AUTOSAR XML (schema 4-0-3)
package /PWC
  composition sw component type PWCDriver
    7 x component:
      Switch: type=SwitchType
      ioHwAb: type=IoHwAb
      EndStopDtc: type=EndStopDtcType
      MotorDriver: type=MotorDriverType
      ObstacleDtc: type=ObstacleDtcType
      WinController: type=WinControllerType
      WinArbitrator: type=WinArbitratorType
    connect ioHwAb.Digital_DigitalSignal_LED1 -> MotorDriver.RunMotor_1
    connect ioHwAb.Digital_DigitalSignal_LED2 -> MotorDriver.RunMotor_2
    connect ioHwAb.Digital_DigitalSignal_Obstacle -> ObstacleDtc.isObstacle
    connect ioHwAb.Digital_DigitalSignal_EndStop -> EndStopDtc.isEndStop
    connect Switch.req -> WinArbitrator.req_d
    connect WinArbitrator.req_a -> WinController.req
    connect WinController.cmd -> MotorDriver.cmd
    connect ObstacleDtc.obstacle -> WinController.obstacle
    connect EndStopDtc.endStop -> WinController.endStop
  system PWCSystem: category=ECU_EXTRACT, system-version=1
    system mapping ImplementationMappings
      sw-impl-mappings:
        7 x swc to impl mapping:
          IoHWAbMapping: component-implementation=IoHwAbImpl, component=RootSwComposition.ioHwAb
          SwitchMapping: component-implementation=SwitchImpl, component=RootSwComposition.Switch
          MotorMapping: component-implementation=MotorDriverImpl, component=RootSwComposition.MotorDriver
          ObstacleMapping: component-implementation=ObstacleDtcImpl, component=RootSwComposition.ObstacleDtc
          EndStopMapping: component-implementation=EndStopDtcImpl, component=RootSwComposition.EndStopDtc
          WinControllerMapping: component-implementation=WinControllerImpl, component=RootSwComposition.WinController
          WinArbitratorMapping: component-implementation=WinArbitratorImpl, component=RootSwComposition.WinArbitrator
    root-software-compositions:
      root sw composition prototype RootSwComposition: software-composition=PWCDriver
package /PWC/Types
  impl type requestType: category=VALUE, compu {0=request_neutral, 1=request_basic_down, 2=request_basic_up, 3=request_express_down, 4=request_express_up}
  impl type commandType: category=VALUE, compu {0=command_neutral, 1=command_down, 2=command_up}
  impl type myBoolean: category=BOOLEAN
  sender receiver interface BasicCommand
    data command: type=commandType
  sender receiver interface BasicRequest
    data request: type=requestType
  sender receiver interface BasicIndicator
    data isPresent: type=myBoolean
package /PWC/SensorsActuators/EndStopDtc
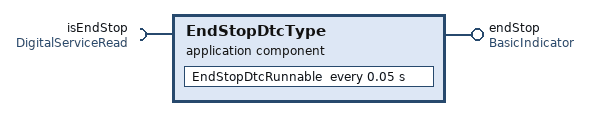
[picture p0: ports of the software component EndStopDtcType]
  application sw component type EndStopDtcType
    require port isEndStop: required-interface=DigitalServiceRead
    provide port endStop: provided-interface=BasicIndicator
    behavior EndStopDtcBehavior: handle-termination-and-restart=NO-SUPPORT
      timing event StepEndStop: start-on-event=EndStopDtcRunnable, period=0.05
      runnable EndStopDtcRunnable
        data-write-access:
          access dataWriteAccess_EndStopDtcRunnable_endStop_isPresent: accessed-variable=endStop.isPresent
        sync call isEndStop_Read: operation=isEndStop.Read, timeout=0.0
  swc implementation EndStopDtcImpl: programming-language=C, vendor-id=0, behavior=EndStopDtcBehavior
    code-descriptors:
      code src: artifact-descriptors=autosar-engineering-object={short-label=artifactDescriptor, category=artifactDescriptorCategory}
    resource consumption resourceConsumption
package /PWC/SensorsActuators/Switch
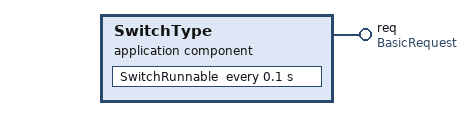
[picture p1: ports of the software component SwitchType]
  application sw component type SwitchType
    provide port req: provided-interface=BasicRequest
    behavior SwitchBehavior: handle-termination-and-restart=NO-SUPPORT
      timing event SwitchEvent: start-on-event=SwitchRunnable, period=0.1
      runnable SwitchRunnable
        data-write-access:
          access dataWriteAccess_SwitchRunnable_req_request: accessed-variable=req.request
  swc implementation SwitchImpl: programming-language=C, vendor-id=0, behavior=SwitchBehavior
    code-descriptors:
      code src: artifact-descriptors=autosar-engineering-object={short-label=artifactDescriptor, category=artifactDescriptorCategory}
    resource consumption resourceConsumption
package /PWC/SensorsActuators/MotorDriver
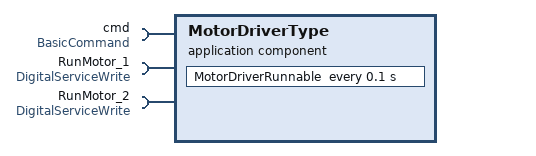
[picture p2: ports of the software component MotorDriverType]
  application sw component type MotorDriverType
    require port cmd: required-interface=BasicCommand
    require port RunMotor_1: required-interface=DigitalServiceWrite
    require port RunMotor_2: required-interface=DigitalServiceWrite
    behavior MotorDriverBehavior: handle-termination-and-restart=NO-SUPPORT
      timing event StepMotor: start-on-event=MotorDriverRunnable, period=0.1
      runnable MotorDriverRunnable
        data-read-access:
          access dataReadAccess_MotorDriverRunnable_cmd_command: accessed-variable=cmd.command
        sync call RunMotor_1_Write: operation=RunMotor_1.Write, timeout=0.0
        sync call RunMotor_2_Write: operation=RunMotor_2.Write, timeout=0.0
  swc implementation MotorDriverImpl: programming-language=C, vendor-id=0, behavior=MotorDriverBehavior
    code-descriptors:
      code src: artifact-descriptors=autosar-engineering-object={short-label=artifactDescriptor, category=artifactDescriptorCategory}
    resource consumption resourceConsumption
package /PWC/SensorsActuators/ObstacleDtc
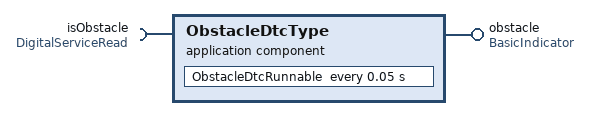
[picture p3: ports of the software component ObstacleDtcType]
  application sw component type ObstacleDtcType
    require port isObstacle: required-interface=DigitalServiceRead
    provide port obstacle: provided-interface=BasicIndicator
    behavior ObstacleDtcBehavior: handle-termination-and-restart=NO-SUPPORT
      timing event StepObstacle: start-on-event=ObstacleDtcRunnable, period=0.05
      runnable ObstacleDtcRunnable
        data-write-access:
          access dataWriteAccess_ObstacleDtcRunnable_obstacle_isPresent: accessed-variable=obstacle.isPresent
        sync call isObstacle_Read: operation=isObstacle.Read, timeout=0.0
  swc implementation ObstacleDtcImpl: programming-language=C, vendor-id=0, behavior=ObstacleDtcBehavior
    code-descriptors:
      code src: artifact-descriptors=autosar-engineering-object={short-label=artifactDescriptor, category=artifactDescriptorCategory}
    resource consumption resourceConsumption
package /PWC/Components/WinArbitrator
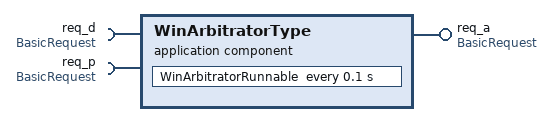
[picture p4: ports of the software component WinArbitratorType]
  application sw component type WinArbitratorType
    require port req_d: required-interface=BasicRequest
    require port req_p: required-interface=BasicRequest
    provide port req_a: provided-interface=BasicRequest
    behavior WinArbitratorBehavior: handle-termination-and-restart=NO-SUPPORT
      timing event StepArbitrator: start-on-event=WinArbitratorRunnable, period=0.1
      runnable WinArbitratorRunnable
        data-read-access:
          access dataReadAccess_WinArbitratorRunnable_req_d_request: accessed-variable=req_d.request
          access dataReadAccess_WinArbitratorRunnable_req_p_request: accessed-variable=req_p.request
        data-write-access:
          access dataWriteAccess_WinArbitratorRunnable_req_a_request: accessed-variable=req_a.request
  swc implementation WinArbitratorImpl: programming-language=C, vendor-id=0, behavior=WinArbitratorBehavior
    code-descriptors:
      code src: artifact-descriptors=autosar-engineering-object={short-label=artifactDescriptor, category=artifactDescriptorCategory}
    resource consumption resourceConsumption
package /PWC/Components/WinController
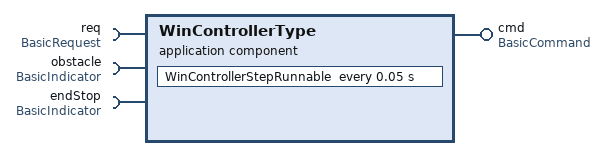
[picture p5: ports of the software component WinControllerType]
  application sw component type WinControllerType
    require port req: required-interface=BasicRequest
    require port obstacle: required-interface=BasicIndicator
    require port endStop: required-interface=BasicIndicator
    provide port cmd: provided-interface=BasicCommand
    behavior WinControllerBehavior: handle-termination-and-restart=NO-SUPPORT
      timing event StepController: start-on-event=WinControllerStepRunnable, period=0.05
      runnable WinControllerStepRunnable: symbol=WinControllerRunnable
        data-read-access:
          access dataReadAccess_WinControllerStepRunnable_req_request: accessed-variable=req.request
          access dataReadAccess_WinControllerStepRunnable_obstacle_isPresent: accessed-variable=obstacle.isPresent
          access dataReadAccess_WinControllerStepRunnable_endStop_isPresent: accessed-variable=endStop.isPresent
        data-write-access:
          access dataWriteAccess_WinControllerStepRunnable_cmd_command: accessed-variable=cmd.command
  swc implementation WinControllerImpl: programming-language=C, vendor-id=0, behavior=WinControllerBehavior
    code-descriptors:
      code src: artifact-descriptors=autosar-engineering-object={short-label=artifactDescriptor, category=artifactDescriptorCategory}
    resource consumption resourceConsumption
package /PWC/Services/IoHwAb
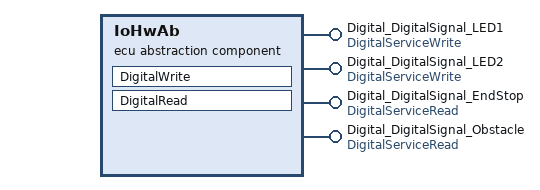
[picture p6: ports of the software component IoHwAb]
  ecu abstraction sw component type IoHwAb
    4 x provide port:
      Digital_DigitalSignal_LED1: provided-interface=DigitalServiceWrite
      Digital_DigitalSignal_LED2: provided-interface=DigitalServiceWrite
      Digital_DigitalSignal_EndStop: provided-interface=DigitalServiceRead
      Digital_DigitalSignal_Obstacle: provided-interface=DigitalServiceRead
    behavior IoHwAbBehavior: handle-termination-and-restart=NO-SUPPORT
      4 x operation invoked event:
        Digital_DigitalSignal_LED1_Write: start-on-event=DigitalWrite, operation=Digital_DigitalSignal_LED1.Write
        Digital_DigitalSignal_LED2_Write: start-on-event=DigitalWrite, operation=Digital_DigitalSignal_LED2.Write
        Digital_DigitalSignal_Obstacle_Read: start-on-event=DigitalRead, operation=Digital_DigitalSignal_Obstacle.Read
        Digital_DigitalSignal_EndStop_Read: start-on-event=DigitalRead, operation=Digital_DigitalSignal_EndStop.Read
      port-api-options:
        {port-defined-argument-value{value=IoHwAb_SignalType_:0, value-type=IoHwAb_SignalType_}, port=Digital_DigitalSignal_LED1}
        {port-defined-argument-value{value=IoHwAb_SignalType_:3, value-type=IoHwAb_SignalType_}, port=Digital_DigitalSignal_LED2}
        {port-defined-argument-value{value=IoHwAb_SignalType_:2, value-type=IoHwAb_SignalType_}, port=Digital_DigitalSignal_Obstacle}
        {port-defined-argument-value{value=IoHwAb_SignalType_:1, value-type=IoHwAb_SignalType_}, port=Digital_DigitalSignal_EndStop}
      runnable DigitalWrite: can-be-invoked-concurrently=true, symbol=IoHwAb_Digital_Write
      runnable DigitalRead: can-be-invoked-concurrently=true, symbol=IoHwAb_Digital_Read
  swc implementation IoHwAbImpl: programming-language=C, vendor-id=60, behavior=IoHwAbBehavior
    code-descriptors:
      code src: artifact-descriptors=autosar-engineering-object={short-label=artifactDescriptor, category=artifactDescriptorCategory}
    resource consumption resourceConsumption
